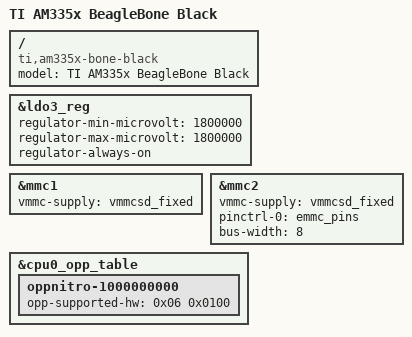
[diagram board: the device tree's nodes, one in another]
// SPDX-License-Identifier: GPL-2.0-only
/*
 * Copyright (C) 2012 Texas Instruments Incorporated - https://www.ti.com/
 */
/dts-v1/;

#include "am33xx.dtsi"
#include "am335x-bone-common-no-capemgr.dtsi"

/ {
	model = "TI AM335x BeagleBone Black";
	compatible = "ti,am335x-bone-black", "ti,am335x-bone", "ti,am33xx";
};

&ldo3_reg {
	regulator-min-microvolt = <1800000>;
	regulator-max-microvolt = <1800000>;
	regulator-always-on;
};

&mmc1 {
	vmmc-supply = <&vmmcsd_fixed>;
};

&mmc2 {
	vmmc-supply = <&vmmcsd_fixed>;
	pinctrl-names = "default";
	pinctrl-0 = <&emmc_pins>;
	bus-width = <8>;
	status = "okay";
};

&cpu0_opp_table {
	/*
	 * All PG 2.0 silicon may not support 1GHz but some of the early
	 * BeagleBone Blacks have PG 2.0 silicon which is guaranteed
	 * to support 1GHz OPP so enable it for PG 2.0 on this board.
	 */
	oppnitro-1000000000 {
		opp-supported-hw = <0x06 0x0100>;
	};
};

#include "am335x-cape-bbb-exp-r.dtsi"
